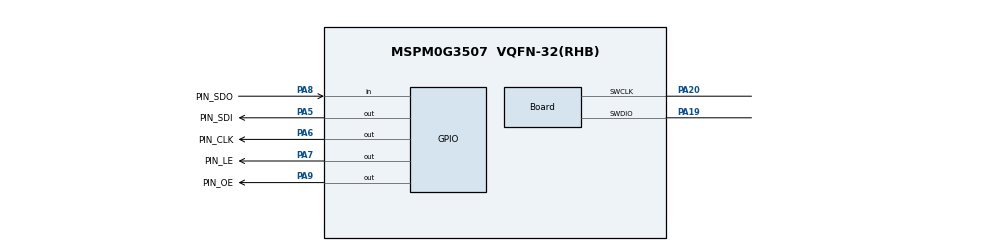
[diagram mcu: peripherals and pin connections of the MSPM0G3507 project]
/**
 * These arguments were used when this file was generated. They will be automatically applied on subsequent loads
 * via the GUI or CLI. Run CLI with '--help' for additional information on how to override these arguments.
 * @cliArgs --device "MSPM0G350X" --part "Default" --package "VQFN-32(RHB)" --product "mspm0_sdk@2.04.00.06"
 * @v2CliArgs --device "MSPM0G3507" --package "VQFN-32(RHB)" --product "mspm0_sdk@2.04.00.06"
 * @versions {"tool":"1.23.0+4000"}
 */

/**
 * Import the modules used in this configuration.
 */
const GPIO   = scripting.addModule("/ti/driverlib/GPIO", {}, false);
const GPIO1  = GPIO.addInstance();
const GPIO2  = GPIO.addInstance();
const GPIO3  = GPIO.addInstance();
const GPIO4  = GPIO.addInstance();
const GPIO5  = GPIO.addInstance();
const SYSCTL = scripting.addModule("/ti/driverlib/SYSCTL");

/**
 * Write custom configuration values to the imported modules.
 */
GPIO1.$name                         = "GPIO_SDI";
GPIO1.associatedPins[0].$name       = "PIN_SDI";
GPIO1.associatedPins[0].pin.$assign = "PA5";

const Board                       = scripting.addModule("/ti/driverlib/Board", {}, false);
Board.peripheral.$assign          = "DEBUGSS";
Board.peripheral.swclkPin.$assign = "PA20";
Board.peripheral.swdioPin.$assign = "PA19";

GPIO2.$name                         = "GPIO_CLK";
GPIO2.associatedPins[0].$name       = "PIN_CLK";
GPIO2.associatedPins[0].pin.$assign = "PA6";

GPIO3.$name                         = "GPIO_LE";
GPIO3.associatedPins[0].$name       = "PIN_LE";
GPIO3.associatedPins[0].pin.$assign = "PA7";

GPIO4.$name                         = "GPIO_SDO";
GPIO4.associatedPins[0].$name       = "PIN_SDO";
GPIO4.associatedPins[0].direction   = "INPUT";
GPIO4.associatedPins[0].pin.$assign = "PA8";

GPIO5.$name                         = "GPIO_OE";
GPIO5.associatedPins[0].$name       = "PIN_OE";
GPIO5.associatedPins[0].pin.$assign = "PA9";

SYSCTL.forceDefaultClkConfig = true;
SYSCTL.clockTreeEn           = true;

const ProjectConfig              = scripting.addModule("/ti/project_config/ProjectConfig", {}, false);
ProjectConfig.migrationCondition = true;
